# S1C31D50 register map
Vendor: Epson; Series: S1C31D50; File version: 1.00
CPU: CM0PLUS r0p1, little endian, MPU, no FPU, VTOR, 2 interrupt priority bits
Registers are 16-bit, read-write, reset 0x0 unless marked. A register's access mark holds for its fields unless they carry their own. Offsets are from the block's base; [hi:lo] are bit positions; {n}, {i} and the like mark numbered series; 'fields as' and 'values as' point back to an identical list.

## QSPI_0 — Quad Synchronous Serial Interface channel 0
Base 0x00200690
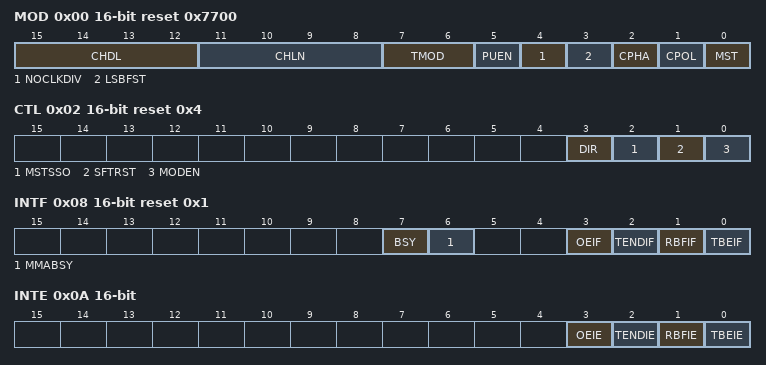
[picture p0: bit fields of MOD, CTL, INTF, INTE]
0x00 MOD reset 0x7700 — QSPI Mode Register
  [15:12] CHDL — These bits determines the number of clocks the serial output data lines will be driven
  [11:8] CHLN — These bits set the number of clocks for data transfer (setting 0x0 is RESERVED)
  [7:6] TMOD — These bits selects the transfer mode
    0=SINGLE (Single mode); 1=DUAL (Dual mode); 2=QUAD (Quad mode)
  [5] PUEN — Enable/Disable pull-up/down
    0=DISABLE (Disabled); 1=ENABLE (Enabled)
  [4] NOCLKDIV — This bit selects QSPICLKn
    0=T16 (T16 / 2); 1=CLK_QSPI (CLK_QSPIn)
  [3] LSBFST — This bit configures the data format
    0=MSB (MSB First); 1=LSB (LSB First)
  [2] CPHA — This bit sets the QSPI clock phase
  [1] CPOL — This bit sets the QSPI clock polarity
  [0] MST — This bit sets the QSPI operating mode
    0=SLAVE (Slave mode); 1=MASTER (Master mode)
0x02 CTL reset 0x4 — QSPI Control Register
  [3] DIR — This bit set the transfer direction of SDIO
  [2] MSTSSO — This bit controls the slave select output pin in master mode only
  [1] SFTRST — This bit issues software reset to QSPI
    on write: 0=NON (No effect); 1=RESET (Resets) | on read: 0=NO_RESET (No Reset pending); 1=RESET (Reset pending)
  [0] MODEN — This bit enables the QSPI operations
    0=DISABLE (QSPI disabled); 1=ENABLE (QSPI enabled)
0x04 TXD — Transmit Data Register
  [15:0] TXD — Transmit data
0x06 RXD ro — Receive Data Register
  [15:0] RXD — Receive data
0x08 INTF reset 0x1 — Interrupt Flag Register
  [7] BSY ro — This bit indicates the QSPI operating status
    0=IDLE (Not Busy); 1=BUSY
  [6] MMABSY ro — This bit indicates the QSPI memory mapped access operating status
    0=IDLE; 1=BUSY
  [3] OEIF write-1-clears — Overrun error interrupt flag
    0=NOT_OCCURED (No cause of interrupt occurred); 1=OCCURED (Cause of interrupt occurred)
  [2] TENDIF write-1-clears — End-of-transmission interrupt flag
    values as OEIF
  [1] RBFIF ro — Receive buffer full interrupt flag (cleared by reading QSPI_0RXD register)
    values as OEIF
  [0] TBEIF ro — Transmit buffer empty interrupt flag (cleared by reading QSPI_0TXD register)
    values as OEIF
0x0A INTE — QSPI Interrupt Enable Register
  [all] fields
    0=DISABLE; 1=ENABLE
  [3] OEIE — Overrun error interrupt enable
  [2] TENDIE — End-of-transmission interrupt enable
  [1] RBFIE — Receive buffer full interrupt enable
  [0] TBEIE — Transmit buffer empty interrupt enable
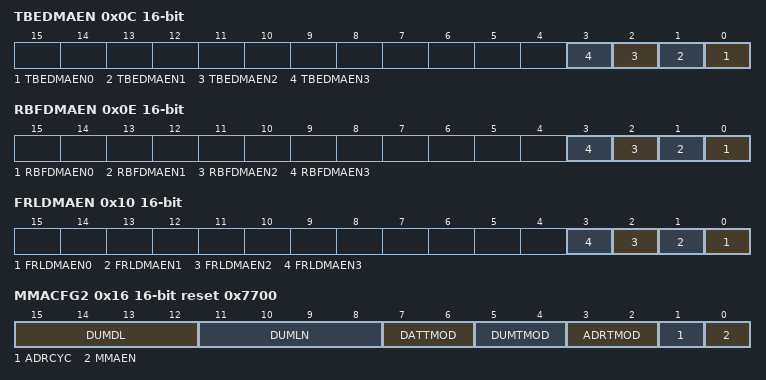
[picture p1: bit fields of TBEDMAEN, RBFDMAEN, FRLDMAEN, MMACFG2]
0x0C TBEDMAEN — Transmit Buffer Empty DMA Enable Register
  [all] fields
    0=DISABLE; 1=ENABLE
  [n] TBEDMAEN{n} (n=0..3) — Transmit Buffer Empty DMA ch{n} request enable
0x0E RBFDMAEN — RBFDMAEN Receive Buffer Full DMA Request Enable Register
  [all] fields
    0=DISABLE; 1=ENABLE
  [n] RBFDMAEN{n} (n=0..3) — RBF DMA ch{n} request enable
0x10 FRLDMAEN — FRLDMAEN QSPI Fifo Read Level Not Empty DMA Request Enable Register
  [all] fields
    0=DISABLE; 1=ENABLE
  [n] FRLDMAEN{n} (n=0..3) — FRL DMA ch{n} request enable
0x12 MMACFG1 — QSPI Memory Mapped Access Configuration Register 1
  [3:0] TCSH — These bits specify the number of clocks for slave select high between non-contiguous address flash memory read
0x14 RMADRH — QSPI Remapping Start Address High Register
  [15:4] RMADR — The most significant bits of register bits will be appended to the input offset address from the system AHB-Lite bus to this QSPI module
0x16 MMACFG2 reset 0x7700 — QSPI Memory Mapped Access Configuration Register 2
  [15:12] DUMDL — These bits determines the number of clocks the serial output data lines will be driven for dummy cycle
  [11:8] DUMLN — These bits set the number of clocks for dummy cycle during host memory mapped access to the external flash
  [7:6] DATTMOD — These bits specify the number of clocks for slave select high between non-contiguous address flash memory read
    0=SINGLE (Single Mode); 1=DUAL (Dual Mode); 2=QUAD (Quad Mode)
  [5:4] DUMTMOD — These bits selects the transfer mode for dummy cycle during host memory mapped access to the external flash
  [3:2] ADRTMOD — These bits selects the transfer mode for address cycle during host memory mapped access to the external flash
  [1] ADRCYC — This bit selects 24-bit or 32-bit address mode used during host memory mapped access to the external flash
    0=24BIT (24bit Address Mode); 1=32BIT (32it Address Mode)
  [0] MMAEN — This bit enables host memory mapped access to the external flash
    0=DISABLE (Disabled); 1=ENABLE (Enabled)
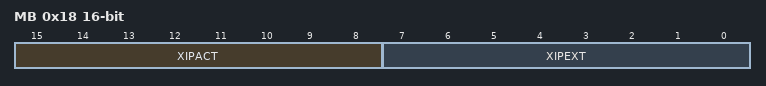
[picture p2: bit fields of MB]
0x18 MB — QSPI Mode Byte Register
  [15:8] XIPACT — These bit sets the mode byte for activation of XIP access during host memory mapped access to the external flash
  [7:0] XIPEXT — These bit sets the mode byte for exit of XIP access during host memory mapped access to the external flash
